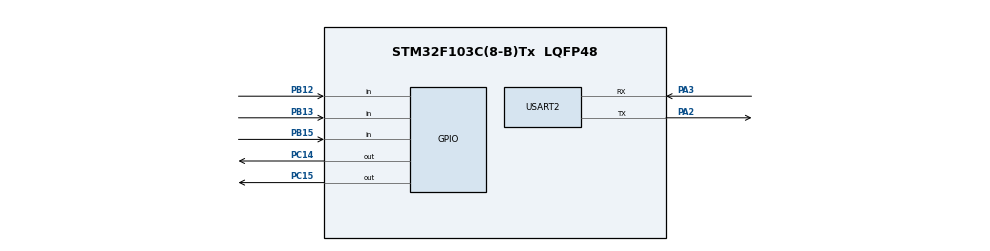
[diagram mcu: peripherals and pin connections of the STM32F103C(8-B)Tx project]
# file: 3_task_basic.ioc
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FREERTOS.Tasks01=task1,0,128,task1Function,Default,NULL,Dynamic,NULL,NULL;task2,0,128,task2Function,Default,NULL,Dynamic,NULL,NULL;task3,0,128,task3Function,Default,NULL,Dynamic,NULL,NULL
Mcu.Family=STM32F1
Mcu.Name=STM32F103C(8-B)Tx
Mcu.Package=LQFP48
NVIC.PriorityGroup=NVIC_PRIORITYGROUP_4
NVIC.TIM1_UP_IRQn=true\:15\:0\:false\:false\:true\:false\:false\:true\:true
NVIC.TimeBase=TIM1_UP_IRQn
NVIC.TimeBaseIP=TIM1
PA13.Mode=Serial_Wire
PA13.Signal=SYS_JTMS-SWDIO
PA14.Mode=Serial_Wire
PA14.Signal=SYS_JTCK-SWCLK
PA2.Mode=Asynchronous
PA2.Signal=USART2_TX
PA3.Mode=Asynchronous
PA3.Signal=USART2_RX
PB12.GPIO_PuPd=GPIO_PULLDOWN
PB12.Signal=GPIO_Input
PB13.GPIO_PuPd=GPIO_PULLDOWN
PB13.Signal=GPIO_Input
PB15.GPIO_PuPd=GPIO_PULLDOWN
PB15.Signal=GPIO_Input
PC14-OSC32_IN.Signal=GPIO_Output
PC15-OSC32_OUT.Signal=GPIO_Output
PD0-OSC_IN.Mode=HSE-External-Oscillator
PD0-OSC_IN.Signal=RCC_OSC_IN
PD1-OSC_OUT.Mode=HSE-External-Oscillator
PD1-OSC_OUT.Signal=RCC_OSC_OUT
ProjectManager.HeapSize=0x200
ProjectManager.StackSize=0x400
ProjectManager.TargetToolchain=MDK-ARM V5.32
RCC.APB1Freq_Value=8000000
RCC.APB2Freq_Value=8000000
USART2.VirtualMode=VM_ASYNC
VP_FREERTOS_VS_CMSIS_V1.Mode=CMSIS_V1
VP_SYS_VS_tim1.Mode=TIM1
board=custom

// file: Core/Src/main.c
/* USER CODE BEGIN Header */
/**
  ******************************************************************************
  * @file           : main.c
  * @brief          : Main program body
  ******************************************************************************
  * @attention
  *
  * Copyright (c) 2022 STMicroelectronics.
  * All rights reserved.
  *
  * This software is licensed under terms that can be found in the LICENSE file
  * in the root directory of this software component.
  * If no LICENSE file comes with this software, it is provided AS-IS.
  *
  ******************************************************************************
  */
/* USER CODE END Header */
#include "main.h"
#include "cmsis_os.h"

/* USER CODE BEGIN Includes */
uint8_t lock = 0;
/* USER CODE END Includes */

UART_HandleTypeDef huart2;

osThreadId task1Handle;
osThreadId task2Handle;
osThreadId task3Handle;

void SystemClock_Config(void);
static void MX_GPIO_Init(void);
static void MX_USART2_UART_Init(void);
void task1Function(void const * argument);
void task2Function(void const * argument);
void task3Function(void const * argument);

int main(void)
{

  /* MCU Configuration--------------------------------------------------------*/

  /* Reset of all peripherals, Initializes the Flash interface and the Systick. */
  HAL_Init();

  /* Configure the system clock */
  SystemClock_Config();

  /* Initialize all configured peripherals */
  MX_GPIO_Init();
  MX_USART2_UART_Init();

  /* Create the thread(s) */
  /* definition and creation of task1 */
  osThreadDef(task1, task1Function, osPriorityNormal, 0, 128);
  task1Handle = osThreadCreate(osThread(task1), NULL);

  /* definition and creation of task2 */
  osThreadDef(task2, task2Function, osPriorityNormal, 0, 128);
  task2Handle = osThreadCreate(osThread(task2), NULL);

  /* definition and creation of task3 */
  osThreadDef(task3, task3Function, osPriorityNormal, 0, 128);
  task3Handle = osThreadCreate(osThread(task3), NULL);

  /* Start scheduler */
  osKernelStart();

  /* We should never get here as control is now taken by the scheduler */
  /* Infinite loop */
  while (1)
  {

  }
}

void SystemClock_Config(void)
{
  RCC_OscInitTypeDef RCC_OscInitStruct = {0};
  RCC_ClkInitTypeDef RCC_ClkInitStruct = {0};

  /** Initializes the RCC Oscillators according to the specified parameters
  * in the RCC_OscInitTypeDef structure.
  */
  RCC_OscInitStruct.OscillatorType = RCC_OSCILLATORTYPE_HSI;
  RCC_OscInitStruct.HSIState = RCC_HSI_ON;
  RCC_OscInitStruct.HSICalibrationValue = RCC_HSICALIBRATION_DEFAULT;
  RCC_OscInitStruct.PLL.PLLState = RCC_PLL_NONE;
  if (HAL_RCC_OscConfig(&RCC_OscInitStruct) != HAL_OK)
  {
    Error_Handler();
  }

  /** Initializes the CPU, AHB and APB buses clocks
  */
  RCC_ClkInitStruct.ClockType = RCC_CLOCKTYPE_HCLK|RCC_CLOCKTYPE_SYSCLK
                              |RCC_CLOCKTYPE_PCLK1|RCC_CLOCKTYPE_PCLK2;
  RCC_ClkInitStruct.SYSCLKSource = RCC_SYSCLKSOURCE_HSI;
  RCC_ClkInitStruct.AHBCLKDivider = RCC_SYSCLK_DIV1;
  RCC_ClkInitStruct.APB1CLKDivider = RCC_HCLK_DIV1;
  RCC_ClkInitStruct.APB2CLKDivider = RCC_HCLK_DIV1;

  if (HAL_RCC_ClockConfig(&RCC_ClkInitStruct, FLASH_LATENCY_0) != HAL_OK)
  {
    Error_Handler();
  }
}

static void MX_USART2_UART_Init(void)
{

  huart2.Instance = USART2;
  huart2.Init.BaudRate = 115200;
  huart2.Init.WordLength = UART_WORDLENGTH_8B;
  huart2.Init.StopBits = UART_STOPBITS_1;
  huart2.Init.Parity = UART_PARITY_NONE;
  huart2.Init.Mode = UART_MODE_TX_RX;
  huart2.Init.HwFlowCtl = UART_HWCONTROL_NONE;
  huart2.Init.OverSampling = UART_OVERSAMPLING_16;
  if (HAL_UART_Init(&huart2) != HAL_OK)
  {
    Error_Handler();
  }

}

static void MX_GPIO_Init(void)
{
  GPIO_InitTypeDef GPIO_InitStruct = {0};

  /* GPIO Ports Clock Enable */
  __HAL_RCC_GPIOC_CLK_ENABLE();
  __HAL_RCC_GPIOD_CLK_ENABLE();
  __HAL_RCC_GPIOA_CLK_ENABLE();
  __HAL_RCC_GPIOB_CLK_ENABLE();

  /*Configure GPIO pin Output Level */
  HAL_GPIO_WritePin(GPIOC, GPIO_PIN_14|GPIO_PIN_15, GPIO_PIN_RESET);

  /*Configure GPIO pins : PC14 PC15 */
  GPIO_InitStruct.Pin = GPIO_PIN_14|GPIO_PIN_15;
  GPIO_InitStruct.Mode = GPIO_MODE_OUTPUT_PP;
  GPIO_InitStruct.Pull = GPIO_NOPULL;
  GPIO_InitStruct.Speed = GPIO_SPEED_FREQ_LOW;
  HAL_GPIO_Init(GPIOC, &GPIO_InitStruct);

  /*Configure GPIO pins : PB12 PB13 PB15 */
  GPIO_InitStruct.Pin = GPIO_PIN_12|GPIO_PIN_13|GPIO_PIN_15;
  GPIO_InitStruct.Mode = GPIO_MODE_INPUT;
  GPIO_InitStruct.Pull = GPIO_PULLDOWN;
  HAL_GPIO_Init(GPIOB, &GPIO_InitStruct);

}

void task1Function(void const * argument)
{
  /* USER CODE BEGIN 5 */
  /* Infinite loop */
  for(;;)
  {
    while(lock==1){};
		HAL_GPIO_TogglePin(GPIOC,GPIO_PIN_14);
		HAL_Delay(300);
  }
  /* USER CODE END 5 */
}

void task2Function(void const * argument)
{
  /* USER CODE BEGIN task2Function */
  /* Infinite loop */
  for(;;)
  {
    if(HAL_GPIO_ReadPin(GPIOB,GPIO_PIN_13) == 1)
		{
			HAL_GPIO_WritePin(GPIOC,GPIO_PIN_15,1);
		}
		if(HAL_GPIO_ReadPin(GPIOB,GPIO_PIN_12) == 1)
		{
			HAL_GPIO_WritePin(GPIOC,GPIO_PIN_15,0);
		}
	}

  /* USER CODE END task2Function */
}

void task3Function(void const * argument)
{
  /* USER CODE BEGIN task3Function */
  /* Infinite loop */
  for(;;)
  {
   if(HAL_GPIO_ReadPin(GPIOB, GPIO_PIN_15) == 1)
	 {
		 lock = !lock;
		 while(HAL_GPIO_ReadPin(GPIOB,GPIO_PIN_15) == 1);
	 }
  }
  /* USER CODE END task3Function */
}

void HAL_TIM_PeriodElapsedCallback(TIM_HandleTypeDef *htim)
{
  if (htim->Instance == TIM1) {
    HAL_IncTick();
  }
}

void Error_Handler(void)
{
  __disable_irq();
  while (1)
  {
  }
}
